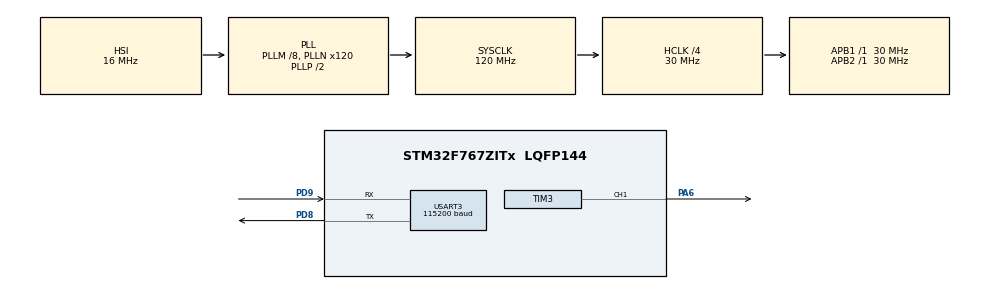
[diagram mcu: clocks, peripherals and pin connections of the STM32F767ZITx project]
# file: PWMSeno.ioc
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CORTEX_M7.default_mode_Activation=1
Dma.Request0=TIM3_CH1/TRIG
Dma.TIM3_CH1/TRIG.0.Direction=DMA_MEMORY_TO_PERIPH
Dma.TIM3_CH1/TRIG.0.FIFOMode=DMA_FIFOMODE_DISABLE
Dma.TIM3_CH1/TRIG.0.Instance=DMA1_Stream4
Dma.TIM3_CH1/TRIG.0.MemDataAlignment=DMA_MDATAALIGN_HALFWORD
Dma.TIM3_CH1/TRIG.0.MemInc=DMA_MINC_ENABLE
Dma.TIM3_CH1/TRIG.0.Mode=DMA_CIRCULAR
Dma.TIM3_CH1/TRIG.0.PeriphDataAlignment=DMA_PDATAALIGN_HALFWORD
Dma.TIM3_CH1/TRIG.0.PeriphInc=DMA_PINC_DISABLE
Dma.TIM3_CH1/TRIG.0.Priority=DMA_PRIORITY_LOW
Mcu.Family=STM32F7
Mcu.Name=STM32F767ZITx
Mcu.Package=LQFP144
NVIC.DMA1_Stream4_IRQn=true\:0\:0\:false\:false\:true\:false\:true\:true
NVIC.PriorityGroup=NVIC_PRIORITYGROUP_4
NVIC.USART3_IRQn=true\:0\:0\:false\:false\:true\:true\:true\:true
PA6.Signal=S_TIM3_CH1
PD8.Mode=Asynchronous
PD8.Signal=USART3_TX
PD9.Mode=Asynchronous
PD9.Signal=USART3_RX
ProjectManager.HeapSize=0x200
ProjectManager.StackSize=0x400
ProjectManager.TargetToolchain=STM32CubeIDE
RCC.AHBCLKDivider=RCC_SYSCLK_DIV4
RCC.AHBFreq_Value=30000000
RCC.APB1Freq_Value=30000000
RCC.APB1TimFreq_Value=30000000
RCC.APB2Freq_Value=30000000
RCC.APB2TimFreq_Value=30000000
RCC.CortexFreq_Value=30000000
RCC.HCLKFreq_Value=30000000
RCC.HSE_VALUE=25000000
RCC.HSI_VALUE=16000000
RCC.LSE_VALUE=32768
RCC.PLLM=8
RCC.PLLN=120
RCC.SYSCLKFreq_VALUE=120000000
RCC.SYSCLKSource=RCC_SYSCLKSOURCE_PLLCLK
RCC.USBFreq_Value=120000000
RCC.VCOOutputFreq_Value=240000000
SH.S_TIM3_CH1.0=TIM3_CH1,PWM Generation1 CH1
TIM3.Channel-PWM\ Generation1\ CH1=TIM_CHANNEL_1
TIM3.Period=200-1
TIM3.Prescaler=10-1
USART3.BaudRate=115200
USART3.VirtualMode-Asynchronous=VM_ASYNC
VP_TIM3_VS_ClockSourceINT.Mode=Internal
board=custom

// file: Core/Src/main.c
/* USER CODE BEGIN Header */
/**
  ******************************************************************************
  * @file           : main.c
  * @brief          : Main program body
  ******************************************************************************
  * @attention
  *
  * Copyright (c) 2026 STMicroelectronics.
  * All rights reserved.
  *
  * This software is licensed under terms that can be found in the LICENSE file
  * in the root directory of this software component.
  * If no LICENSE file comes with this software, it is provided AS-IS.
  *
  ******************************************************************************
  */
/* USER CODE END Header */
#include "main.h"

/* USER CODE BEGIN Includes */

#include "math.h"
#include <stdlib.h>

#define DOISPI 6.2831853 // Aumentada a precisão do PI

// --- MODIFICAÇÕES NAS VARIÁVEIS ---
uint16_t seno[250];             // VETOR CONTENDO OS "ANGULOS" CALCULADOS
uint16_t i;                     // VARIÁVEL DE CONTROLE EM LOOPS
uint32_t frequencia_nativa = 30000000; // FREQUENCIA DEFINIDA VIA MX PARA O CLOCK INTERNO E OS BARRAMENTOS DOS TIMERS
uint16_t amostras = 250;              // QUANTIDADE DE ESTOUROS NECESSÁRIOS PARA DETERMINAR UMA FREQUÊNCIA IGUAL A 60 HZ PARA A SENOIDE
uint16_t estouro = 200;               // ARR DO TIMER
uint8_t buffer[4];                    // VETOR QUE ARMAZENA OS BYTES RECEBIDOS PELA PLACA VIA UART
uint32_t frequencia_desejada;         // VALOR DA FREQUENCIA QUE SE DESEJA DETERMINAR PARA A SENOIDE
uint8_t atualizar_onda = 0;     // FLAG DE CONTROLE DA ATUALIZAÇAO DOS VALORES DE SENO PELO DMA

/* USER CODE END Includes */

TIM_HandleTypeDef htim3;
DMA_HandleTypeDef hdma_tim3_ch1_trig;

UART_HandleTypeDef huart3;

void SystemClock_Config(void);  // INICIALIZAÇÃO DOS CLOCKS
static void MPU_Config(void);
static void MX_GPIO_Init(void); // INICIALIZAÇÃO DOS GPIO'S
static void MX_DMA_Init(void);  // INICIALIZAÇÃO DO DMA
static void MX_TIM3_Init(void); // INICIALIZAÇÃO DO TIMER 3
static void MX_USART3_UART_Init(void); // INICIALIZAÇÃO DA USART3 (PRE-DEFINIDA PARA O ST-LINK)

void HAL_UART_RxCpltCallback(UART_HandleTypeDef *huart) // FUNCAO DE CALLBACK DA UART VIA INTERRUPCAO
{
	if(huart->Instance==USART3){

		buffer[3] = '\0';                                 // DETERMINACAO DO ULTIMO VALOR DO BUFFER COMO SENDO O CARACTER DE ENCERRAMENTO DA DIGITACAO PELA UART
		frequencia_desejada = atol((char*)buffer);        // CONVERSAO DO VALOR RECEBIDO VIA UART (ASCII) PARA INTEIRO

		if(frequencia_desejada > 0){

			uint32_t novo_arr = 12000 / frequencia_desejada; // CALCULO DO NOVO ARR PARA O VALOR DA FREQUENCIA RECEBIDO VIA UART

			estouro = novo_arr;                              // ATUALIZACAO DA VARIAVEL QUE DETERMINA O ARR DO TIMER 3

			__HAL_TIM_SET_AUTORELOAD(&htim3, estouro - 1);  // SETANDO O NOVO VALOR DO ARR DIRETAMENTE
			atualizar_onda = 1;                             // ATUALIZANDO FLAG DE ATUALIZACAO DE ORQUESTRACAO DA SENOIDE
		}
	}

	for(int x=0; x<4; x++) {

    buffer[x] = 0;                                   // LIMPANDO TODOS OS ESPAÇOS DO BUFFER

  }

	HAL_UART_Receive_IT(&huart3, buffer, 4);           // FUNCAO DE RECEBIMENTO DO CARACTERES DO BUFFER VIA UART EM REGIME DE INTERRUPCAO
}

int main(void)
{

  /* MPU Configuration--------------------------------------------------------*/
  MPU_Config();

  /* MCU Configuration--------------------------------------------------------*/

  /* Reset of all peripherals, Initializes the Flash interface and the Systick. */
  HAL_Init();

  /* Configure the system clock */
  SystemClock_Config();

  /* Initialize all configured peripherals */
  MX_GPIO_Init();
  MX_DMA_Init();
  MX_TIM3_Init();
  MX_USART3_UART_Init();
  /* USER CODE BEGIN 2 */

  //
  for(i = 0; i < amostras; i++){

	  seno[i] =  ((sin(i * (DOISPI / amostras))) + 1 ) * (estouro / 2);       // CALCULANDO OS VALORES "CONVERTIDOS" DE PWM PARA SENOIDAL

  }

  HAL_TIM_PWM_Start_DMA(&htim3, TIM_CHANNEL_1, (uint32_t *)seno, amostras); // INICIANDO O PWM EM REGIME DMA (DIRECT MEMORY ACCESS)

  HAL_UART_Receive_IT(&huart3, buffer, 4);                                  // CHAMANDO NOVAMENTE FUNCAO QUE RECEBE VALORES DO BUFFER (DETERMINANDO A NOVA ONDA COM OS NOVOS VALORES SENOIDAIS)

  /* USER CODE END 2 */

  /* Infinite loop */
  /* USER CODE BEGIN WHILE */
  while (1)
  {

      if (atualizar_onda == 1)
      {
          for(i = 0; i < amostras; i++){

              seno[i] = ((sin(i * (DOISPI / amostras))) + 1 ) * (estouro / 2);  // RECALCULANDO OS VALORES DE SENO A FIM DE RESTAURAR OS VALORES QUE O PWM DETERMINA PARA O SINAL COM A NOVA FREQUENCIA

          }

          atualizar_onda = 0;                                                   // ATUALIZANDO VALOR DA FLAG DE CONTROLE PARA ZERO, DETERMINANDO A ESPERA DO PROXIMO VALOR DE FREQUENCIA
      }

    /* USER CODE END WHILE */

  }
}

void SystemClock_Config(void)
{
  RCC_OscInitTypeDef RCC_OscInitStruct = {0};
  RCC_ClkInitTypeDef RCC_ClkInitStruct = {0};

  /** Configure the main internal regulator output voltage
  */
  __HAL_RCC_PWR_CLK_ENABLE();
  __HAL_PWR_VOLTAGESCALING_CONFIG(PWR_REGULATOR_VOLTAGE_SCALE3);

  /** Initializes the RCC Oscillators according to the specified parameters
  * in the RCC_OscInitTypeDef structure.
  */
  RCC_OscInitStruct.OscillatorType = RCC_OSCILLATORTYPE_HSI;
  RCC_OscInitStruct.HSIState = RCC_HSI_ON;
  RCC_OscInitStruct.HSICalibrationValue = RCC_HSICALIBRATION_DEFAULT;
  RCC_OscInitStruct.PLL.PLLState = RCC_PLL_ON;
  RCC_OscInitStruct.PLL.PLLSource = RCC_PLLSOURCE_HSI;
  RCC_OscInitStruct.PLL.PLLM = 8;
  RCC_OscInitStruct.PLL.PLLN = 120;
  RCC_OscInitStruct.PLL.PLLP = RCC_PLLP_DIV2;
  RCC_OscInitStruct.PLL.PLLQ = 2;
  RCC_OscInitStruct.PLL.PLLR = 2;
  if (HAL_RCC_OscConfig(&RCC_OscInitStruct) != HAL_OK)
  {
    Error_Handler();
  }

  /** Initializes the CPU, AHB and APB buses clocks
  */
  RCC_ClkInitStruct.ClockType = RCC_CLOCKTYPE_HCLK|RCC_CLOCKTYPE_SYSCLK
                              |RCC_CLOCKTYPE_PCLK1|RCC_CLOCKTYPE_PCLK2;
  RCC_ClkInitStruct.SYSCLKSource = RCC_SYSCLKSOURCE_PLLCLK;
  RCC_ClkInitStruct.AHBCLKDivider = RCC_SYSCLK_DIV4;
  RCC_ClkInitStruct.APB1CLKDivider = RCC_HCLK_DIV1;
  RCC_ClkInitStruct.APB2CLKDivider = RCC_HCLK_DIV1;

  if (HAL_RCC_ClockConfig(&RCC_ClkInitStruct, FLASH_LATENCY_0) != HAL_OK)
  {
    Error_Handler();
  }
}

static void MX_TIM3_Init(void)
{

  TIM_ClockConfigTypeDef sClockSourceConfig = {0};
  TIM_MasterConfigTypeDef sMasterConfig = {0};
  TIM_OC_InitTypeDef sConfigOC = {0};

  htim3.Instance = TIM3;
  htim3.Init.Prescaler = 10-1;
  htim3.Init.CounterMode = TIM_COUNTERMODE_UP;
  htim3.Init.Period = estouro-1;
  htim3.Init.ClockDivision = TIM_CLOCKDIVISION_DIV1;
  htim3.Init.AutoReloadPreload = TIM_AUTORELOAD_PRELOAD_DISABLE;
  if (HAL_TIM_Base_Init(&htim3) != HAL_OK)
  {
    Error_Handler();
  }
  sClockSourceConfig.ClockSource = TIM_CLOCKSOURCE_INTERNAL;
  if (HAL_TIM_ConfigClockSource(&htim3, &sClockSourceConfig) != HAL_OK)
  {
    Error_Handler();
  }
  if (HAL_TIM_PWM_Init(&htim3) != HAL_OK)
  {
    Error_Handler();
  }
  sMasterConfig.MasterOutputTrigger = TIM_TRGO_RESET;
  sMasterConfig.MasterSlaveMode = TIM_MASTERSLAVEMODE_DISABLE;
  if (HAL_TIMEx_MasterConfigSynchronization(&htim3, &sMasterConfig) != HAL_OK)
  {
    Error_Handler();
  }
  sConfigOC.OCMode = TIM_OCMODE_PWM1;
  sConfigOC.Pulse = 0;
  sConfigOC.OCPolarity = TIM_OCPOLARITY_HIGH;
  sConfigOC.OCFastMode = TIM_OCFAST_DISABLE;
  if (HAL_TIM_PWM_ConfigChannel(&htim3, &sConfigOC, TIM_CHANNEL_1) != HAL_OK)
  {
    Error_Handler();
  }
  HAL_TIM_MspPostInit(&htim3);

}

static void MX_USART3_UART_Init(void)
{

  huart3.Instance = USART3;
  huart3.Init.BaudRate = 115200;
  huart3.Init.WordLength = UART_WORDLENGTH_8B;
  huart3.Init.StopBits = UART_STOPBITS_1;
  huart3.Init.Parity = UART_PARITY_NONE;
  huart3.Init.Mode = UART_MODE_TX_RX;
  huart3.Init.HwFlowCtl = UART_HWCONTROL_NONE;
  huart3.Init.OverSampling = UART_OVERSAMPLING_16;
  huart3.Init.OneBitSampling = UART_ONE_BIT_SAMPLE_DISABLE;
  huart3.AdvancedInit.AdvFeatureInit = UART_ADVFEATURE_NO_INIT;
  if (HAL_UART_Init(&huart3) != HAL_OK)
  {
    Error_Handler();
  }

}

static void MX_DMA_Init(void)
{

  /* DMA controller clock enable */
  __HAL_RCC_DMA1_CLK_ENABLE();

  /* DMA interrupt init */
  /* DMA1_Stream4_IRQn interrupt configuration */
  HAL_NVIC_SetPriority(DMA1_Stream4_IRQn, 0, 0);
  HAL_NVIC_EnableIRQ(DMA1_Stream4_IRQn);

}

static void MX_GPIO_Init(void)
{

  /* GPIO Ports Clock Enable */
  __HAL_RCC_GPIOA_CLK_ENABLE();
  __HAL_RCC_GPIOD_CLK_ENABLE();

}

 /* MPU Configuration */

void MPU_Config(void)
{
  MPU_Region_InitTypeDef MPU_InitStruct = {0};

  /* Disables the MPU */
  HAL_MPU_Disable();

  /** Initializes and configures the Region and the memory to be protected
  */
  MPU_InitStruct.Enable = MPU_REGION_ENABLE;
  MPU_InitStruct.Number = MPU_REGION_NUMBER0;
  MPU_InitStruct.BaseAddress = 0x0;
  MPU_InitStruct.Size = MPU_REGION_SIZE_4GB;
  MPU_InitStruct.SubRegionDisable = 0x87;
  MPU_InitStruct.TypeExtField = MPU_TEX_LEVEL0;
  MPU_InitStruct.AccessPermission = MPU_REGION_NO_ACCESS;
  MPU_InitStruct.DisableExec = MPU_INSTRUCTION_ACCESS_DISABLE;
  MPU_InitStruct.IsShareable = MPU_ACCESS_SHAREABLE;
  MPU_InitStruct.IsCacheable = MPU_ACCESS_NOT_CACHEABLE;
  MPU_InitStruct.IsBufferable = MPU_ACCESS_NOT_BUFFERABLE;

  HAL_MPU_ConfigRegion(&MPU_InitStruct);
  /* Enables the MPU */
  HAL_MPU_Enable(MPU_PRIVILEGED_DEFAULT);

}

void Error_Handler(void)
{
  __disable_irq();
  while (1)
  {
  }
}
